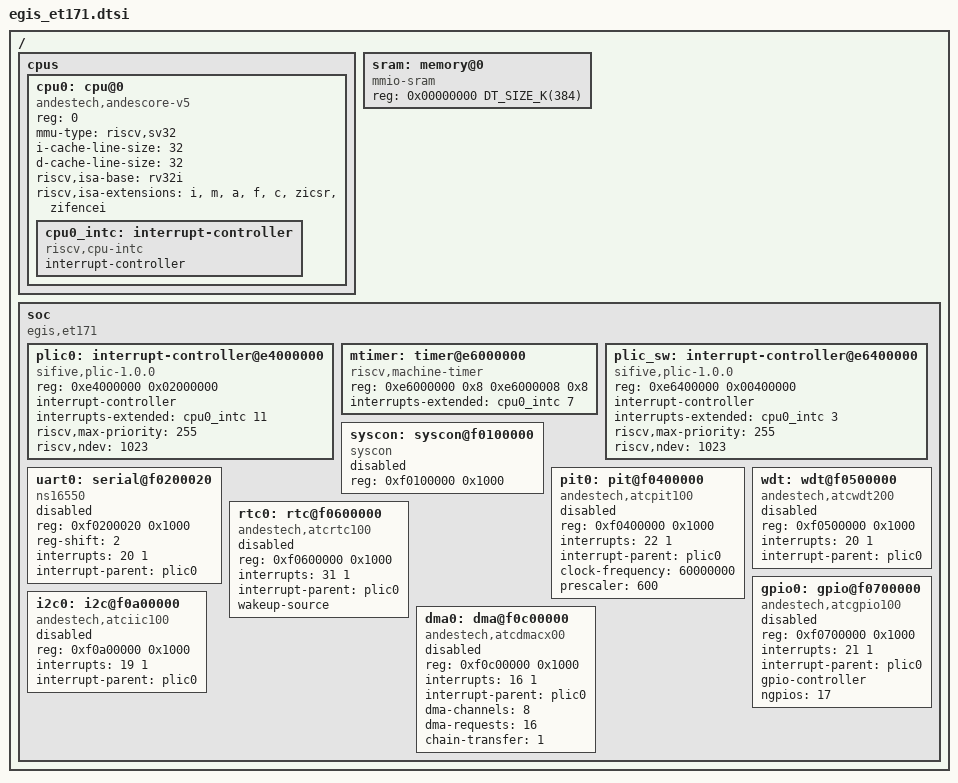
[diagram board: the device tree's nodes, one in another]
/*
 * Copyright (c) 2025 Egis Technology Inc.
 *
 * SPDX-License-Identifier: Apache-2.0
 */

/dts-v1/;
#include <zephyr/dt-bindings/gpio/gpio.h>
#include <mem.h>

/ {
	#address-cells = <1>;
	#size-cells = <1>;

	cpus {
		#address-cells = <1>;
		#size-cells = <0>;

		cpu0: cpu@0 {
			compatible = "andestech,andescore-v5", "riscv";
			reg = <0>;
			device_type = "cpu";
			mmu-type = "riscv,sv32";
			i-cache-line-size = <32>;
			d-cache-line-size = <32>;
			riscv,isa-base = "rv32i";
			riscv,isa-extensions = "i", "m", "a", "f", "c", "zicsr", "zifencei";

			cpu0_intc: interrupt-controller {
				compatible = "riscv,cpu-intc";
				#address-cells = <0>;
				#interrupt-cells = <1>;
				interrupt-controller;
			};
		};
	};

	sram: memory@0 {
		compatible = "mmio-sram";
		reg = <0x00000000 DT_SIZE_K(384)>;
		device_type = "memory";
	};

	soc {
		compatible = "egis,et171";
		ranges;
		#address-cells = <1>;
		#size-cells = <1>;

		plic0: interrupt-controller@e4000000 {
			compatible = "sifive,plic-1.0.0", "andestech,nceplic100";
			reg = <0xe4000000 0x02000000>;
			#address-cells = <1>;
			#interrupt-cells = <2>;
			interrupt-controller;
			interrupts-extended = <&cpu0_intc 11>;
			riscv,max-priority = <255>;
			riscv,ndev = <1023>;
		};

		mtimer: timer@e6000000 {
			compatible = "riscv,machine-timer";
			reg = <0xe6000000 0x8 0xe6000008 0x8>;
			reg-names = "mtime", "mtimecmp";
			interrupts-extended = <&cpu0_intc 7>;
		};

		plic_sw: interrupt-controller@e6400000 {
			compatible = "sifive,plic-1.0.0", "andestech,nceplic100";
			reg = <0xe6400000 0x00400000>;
			#address-cells = <1>;
			#interrupt-cells = <2>;
			interrupt-controller;
			interrupts-extended = <&cpu0_intc 3>;
			riscv,max-priority = <255>;
			riscv,ndev = <1023>;
		};

		syscon: syscon@f0100000 {
			compatible = "syscon", "egis,et171-aosmu";
			reg = <0xf0100000 0x1000>;
			status = "disabled";
		};

		uart0: serial@f0200020 {
			compatible = "ns16550";
			reg = <0xf0200020 0x1000>;
			reg-shift = <2>;
			interrupts = <20 1>;
			interrupt-parent = <&plic0>;
			status = "disabled";
		};

		pit0: pit@f0400000 {
			compatible = "andestech,atcpit100";
			reg = <0xf0400000 0x1000>;
			interrupts = <22 1>;
			interrupt-parent = <&plic0>;
			clock-frequency = <60000000>;
			prescaler = <600>;
			status = "disabled";
		};

		wdt: wdt@f0500000 {
			compatible = "andestech,atcwdt200";
			reg = <0xf0500000 0x1000>;
			interrupts = <20 1>;
			interrupt-parent = <&plic0>;
			status = "disabled";
		};

		rtc0: rtc@f0600000 {
			compatible = "andestech,atcrtc100";
			reg = <0xf0600000 0x1000>;
			interrupts = <31 1>;
			interrupt-parent = <&plic0>;
			wakeup-source;
			status = "disabled";
		};

		gpio0: gpio@f0700000 {
			compatible = "andestech,atcgpio100";
			reg = <0xf0700000 0x1000>;
			interrupts = <21 1>;
			interrupt-parent = <&plic0>;
			gpio-controller;
			ngpios = <17>;
			#gpio-cells = <2>;
			status = "disabled";
		};

		i2c0: i2c@f0a00000 {
			compatible = "andestech,atciic100";
			reg = <0xf0a00000 0x1000>;
			interrupts = <19 1>;
			interrupt-parent = <&plic0>;
			#address-cells = <1>;
			#size-cells = <0>;
			status = "disabled";
		};

		dma0: dma@f0c00000 {
			compatible = "andestech,atcdmacx00";
			reg = <0xf0c00000 0x1000>;
			interrupts = <16 1>;
			interrupt-parent = <&plic0>;
			dma-channels = <8>;
			dma-requests = <16>;
			chain-transfer = <1>;
			#dma-cells = <3>;
			status = "disabled";
		};
	};
};
